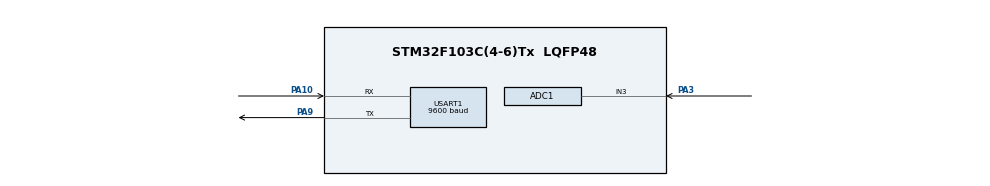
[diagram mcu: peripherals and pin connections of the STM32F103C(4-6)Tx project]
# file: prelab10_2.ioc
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ADC1.Channel-3\#ChannelRegularConversion=ADC_CHANNEL_3
ADC1.NbrOfConversionFlag=1
ADC1.Rank-3\#ChannelRegularConversion=1
ADC1.SamplingTime-3\#ChannelRegularConversion=ADC_SAMPLETIME_1CYCLE_5
ADC1.master=1
Dma.Request0=USART1_TX
Dma.USART1_TX.0.Direction=DMA_MEMORY_TO_PERIPH
Dma.USART1_TX.0.Instance=DMA1_Channel4
Dma.USART1_TX.0.MemDataAlignment=DMA_MDATAALIGN_WORD
Dma.USART1_TX.0.MemInc=DMA_MINC_ENABLE
Dma.USART1_TX.0.Mode=DMA_CIRCULAR
Dma.USART1_TX.0.PeriphDataAlignment=DMA_PDATAALIGN_WORD
Dma.USART1_TX.0.PeriphInc=DMA_PINC_DISABLE
Dma.USART1_TX.0.Priority=DMA_PRIORITY_LOW
Mcu.Family=STM32F1
Mcu.Name=STM32F103C(4-6)Tx
Mcu.Package=LQFP48
NVIC.DMA1_Channel4_IRQn=true\:0\:0\:false\:false\:true\:false\:true\:true
NVIC.PriorityGroup=NVIC_PRIORITYGROUP_4
PA10.Mode=Asynchronous
PA10.Signal=USART1_RX
PA3.Signal=ADCx_IN3
PA9.Mode=Asynchronous
PA9.Signal=USART1_TX
ProjectManager.HeapSize=0x200
ProjectManager.StackSize=0x400
ProjectManager.TargetToolchain=MDK-ARM V5.32
RCC.APB1Freq_Value=8000000
RCC.APB2Freq_Value=8000000
SH.ADCx_IN3.0=ADC1_IN3,IN3
USART1.BaudRate=9600
USART1.VirtualMode=VM_ASYNC
VP_SYS_VS_ND.Mode=No_Debug
board=custom

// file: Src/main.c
/* USER CODE BEGIN Header */
/**
  ******************************************************************************
  * @file           : main.c
  * @brief          : Main program body
  ******************************************************************************
  * @attention
  *
  * Copyright (c) 2022 STMicroelectronics.
  * All rights reserved.
  *
  * This software is licensed under terms that can be found in the LICENSE file
  * in the root directory of this software component.
  * If no LICENSE file comes with this software, it is provided AS-IS.
  *
  ******************************************************************************
  */
/* USER CODE END Header */
#include "main.h"

/* USER CODE BEGIN Includes */
#include "stdio.h"
#include "string.h"
/* USER CODE END Includes */

/* USER CODE BEGIN PTD */
uint16_t adcBuff[1] = {0};		//to store converted values
uint16_t adcData[1] = {0};		//to use as a second buffer
uint8_t convEnd = 0;
/* USER CODE END PTD */

 ADC_HandleTypeDef hadc1;

UART_HandleTypeDef huart1;
DMA_HandleTypeDef hdma_usart1_tx;

void SystemClock_Config(void);
static void MX_GPIO_Init(void);
static void MX_DMA_Init(void);
static void MX_ADC1_Init(void);
static void MX_USART1_UART_Init(void);
/* USER CODE BEGIN PFP */
void HAL_ADC_ConvCpltCallback(ADC_HandleTypeDef* hadc)
{
	if(hadc == &hadc1)								//check which adc made interrupt
	{
		for(int i = 0; i < 1; i++)
		{
			adcData[i] = adcBuff[i];				//copy data to second buffer
		}
		convEnd = 1;								//set conv end flag
	}
}
/* USER CODE END PFP */

int main(void)
{

  /* MCU Configuration--------------------------------------------------------*/

  /* Reset of all peripherals, Initializes the Flash interface and the Systick. */
  HAL_Init();

  /* Configure the system clock */
  SystemClock_Config();

  /* Initialize all configured peripherals */
  MX_GPIO_Init();
  MX_DMA_Init();
  MX_ADC1_Init();
  MX_USART1_UART_Init();
  /* USER CODE BEGIN 2 */
HAL_ADC_Start_DMA(&hadc1, (uint32_t *)adcBuff, 1);
  /* USER CODE END 2 */

  /* Infinite loop */
  /* USER CODE BEGIN WHILE */
  while (1)
  {
		 char txt[30];
		  sprintf(txt, "ADC Val: %d\n\r", adcData[0]);			//print value in a text
		  HAL_UART_Transmit_DMA(&huart1, (uint8_t *)txt, strlen(txt));		//send text over UART
		  HAL_Delay(1000);
    /* USER CODE END WHILE */

  }
}

void SystemClock_Config(void)
{
  RCC_OscInitTypeDef RCC_OscInitStruct = {0};
  RCC_ClkInitTypeDef RCC_ClkInitStruct = {0};
  RCC_PeriphCLKInitTypeDef PeriphClkInit = {0};

  /** Initializes the RCC Oscillators according to the specified parameters
  * in the RCC_OscInitTypeDef structure.
  */
  RCC_OscInitStruct.OscillatorType = RCC_OSCILLATORTYPE_HSI;
  RCC_OscInitStruct.HSIState = RCC_HSI_ON;
  RCC_OscInitStruct.HSICalibrationValue = RCC_HSICALIBRATION_DEFAULT;
  RCC_OscInitStruct.PLL.PLLState = RCC_PLL_NONE;
  if (HAL_RCC_OscConfig(&RCC_OscInitStruct) != HAL_OK)
  {
    Error_Handler();
  }

  /** Initializes the CPU, AHB and APB buses clocks
  */
  RCC_ClkInitStruct.ClockType = RCC_CLOCKTYPE_HCLK|RCC_CLOCKTYPE_SYSCLK
                              |RCC_CLOCKTYPE_PCLK1|RCC_CLOCKTYPE_PCLK2;
  RCC_ClkInitStruct.SYSCLKSource = RCC_SYSCLKSOURCE_HSI;
  RCC_ClkInitStruct.AHBCLKDivider = RCC_SYSCLK_DIV1;
  RCC_ClkInitStruct.APB1CLKDivider = RCC_HCLK_DIV1;
  RCC_ClkInitStruct.APB2CLKDivider = RCC_HCLK_DIV1;

  if (HAL_RCC_ClockConfig(&RCC_ClkInitStruct, FLASH_LATENCY_0) != HAL_OK)
  {
    Error_Handler();
  }
  PeriphClkInit.PeriphClockSelection = RCC_PERIPHCLK_ADC;
  PeriphClkInit.AdcClockSelection = RCC_ADCPCLK2_DIV2;
  if (HAL_RCCEx_PeriphCLKConfig(&PeriphClkInit) != HAL_OK)
  {
    Error_Handler();
  }
}

static void MX_ADC1_Init(void)
{

  ADC_ChannelConfTypeDef sConfig = {0};

  /** Common config
  */
  hadc1.Instance = ADC1;
  hadc1.Init.ScanConvMode = ADC_SCAN_DISABLE;
  hadc1.Init.ContinuousConvMode = DISABLE;
  hadc1.Init.DiscontinuousConvMode = DISABLE;
  hadc1.Init.ExternalTrigConv = ADC_SOFTWARE_START;
  hadc1.Init.DataAlign = ADC_DATAALIGN_RIGHT;
  hadc1.Init.NbrOfConversion = 1;
  if (HAL_ADC_Init(&hadc1) != HAL_OK)
  {
    Error_Handler();
  }

  /** Configure Regular Channel
  */
  sConfig.Channel = ADC_CHANNEL_3;
  sConfig.Rank = ADC_REGULAR_RANK_1;
  sConfig.SamplingTime = ADC_SAMPLETIME_1CYCLE_5;
  if (HAL_ADC_ConfigChannel(&hadc1, &sConfig) != HAL_OK)
  {
    Error_Handler();
  }

}

static void MX_USART1_UART_Init(void)
{

  huart1.Instance = USART1;
  huart1.Init.BaudRate = 9600;
  huart1.Init.WordLength = UART_WORDLENGTH_8B;
  huart1.Init.StopBits = UART_STOPBITS_1;
  huart1.Init.Parity = UART_PARITY_NONE;
  huart1.Init.Mode = UART_MODE_TX_RX;
  huart1.Init.HwFlowCtl = UART_HWCONTROL_NONE;
  huart1.Init.OverSampling = UART_OVERSAMPLING_16;
  if (HAL_UART_Init(&huart1) != HAL_OK)
  {
    Error_Handler();
  }

}

static void MX_DMA_Init(void)
{

  /* DMA controller clock enable */
  __HAL_RCC_DMA1_CLK_ENABLE();

  /* DMA interrupt init */
  /* DMA1_Channel4_IRQn interrupt configuration */
  HAL_NVIC_SetPriority(DMA1_Channel4_IRQn, 0, 0);
  HAL_NVIC_EnableIRQ(DMA1_Channel4_IRQn);

}

static void MX_GPIO_Init(void)
{

  /* GPIO Ports Clock Enable */
  __HAL_RCC_GPIOA_CLK_ENABLE();

}

void Error_Handler(void)
{
  __disable_irq();
  while (1)
  {
  }
}
